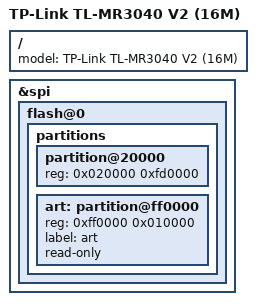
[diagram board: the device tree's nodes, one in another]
// SPDX-License-Identifier: GPL-2.0
/dts-v1/;

#include "ar9331_tplink_tl-mr3040-v2.dts"

/ {
	model = "TP-Link TL-MR3040 V2 (16M)";
};

&spi {
	flash@0 {
		partitions {
			partition@20000 {
				reg = <0x020000 0xfd0000>;
			};

			/delete-node/ partition@3f0000;
			art: partition@ff0000 {
				reg = <0xff0000 0x010000>;
				label = "art";
				read-only;
			};
		};
	};
};
